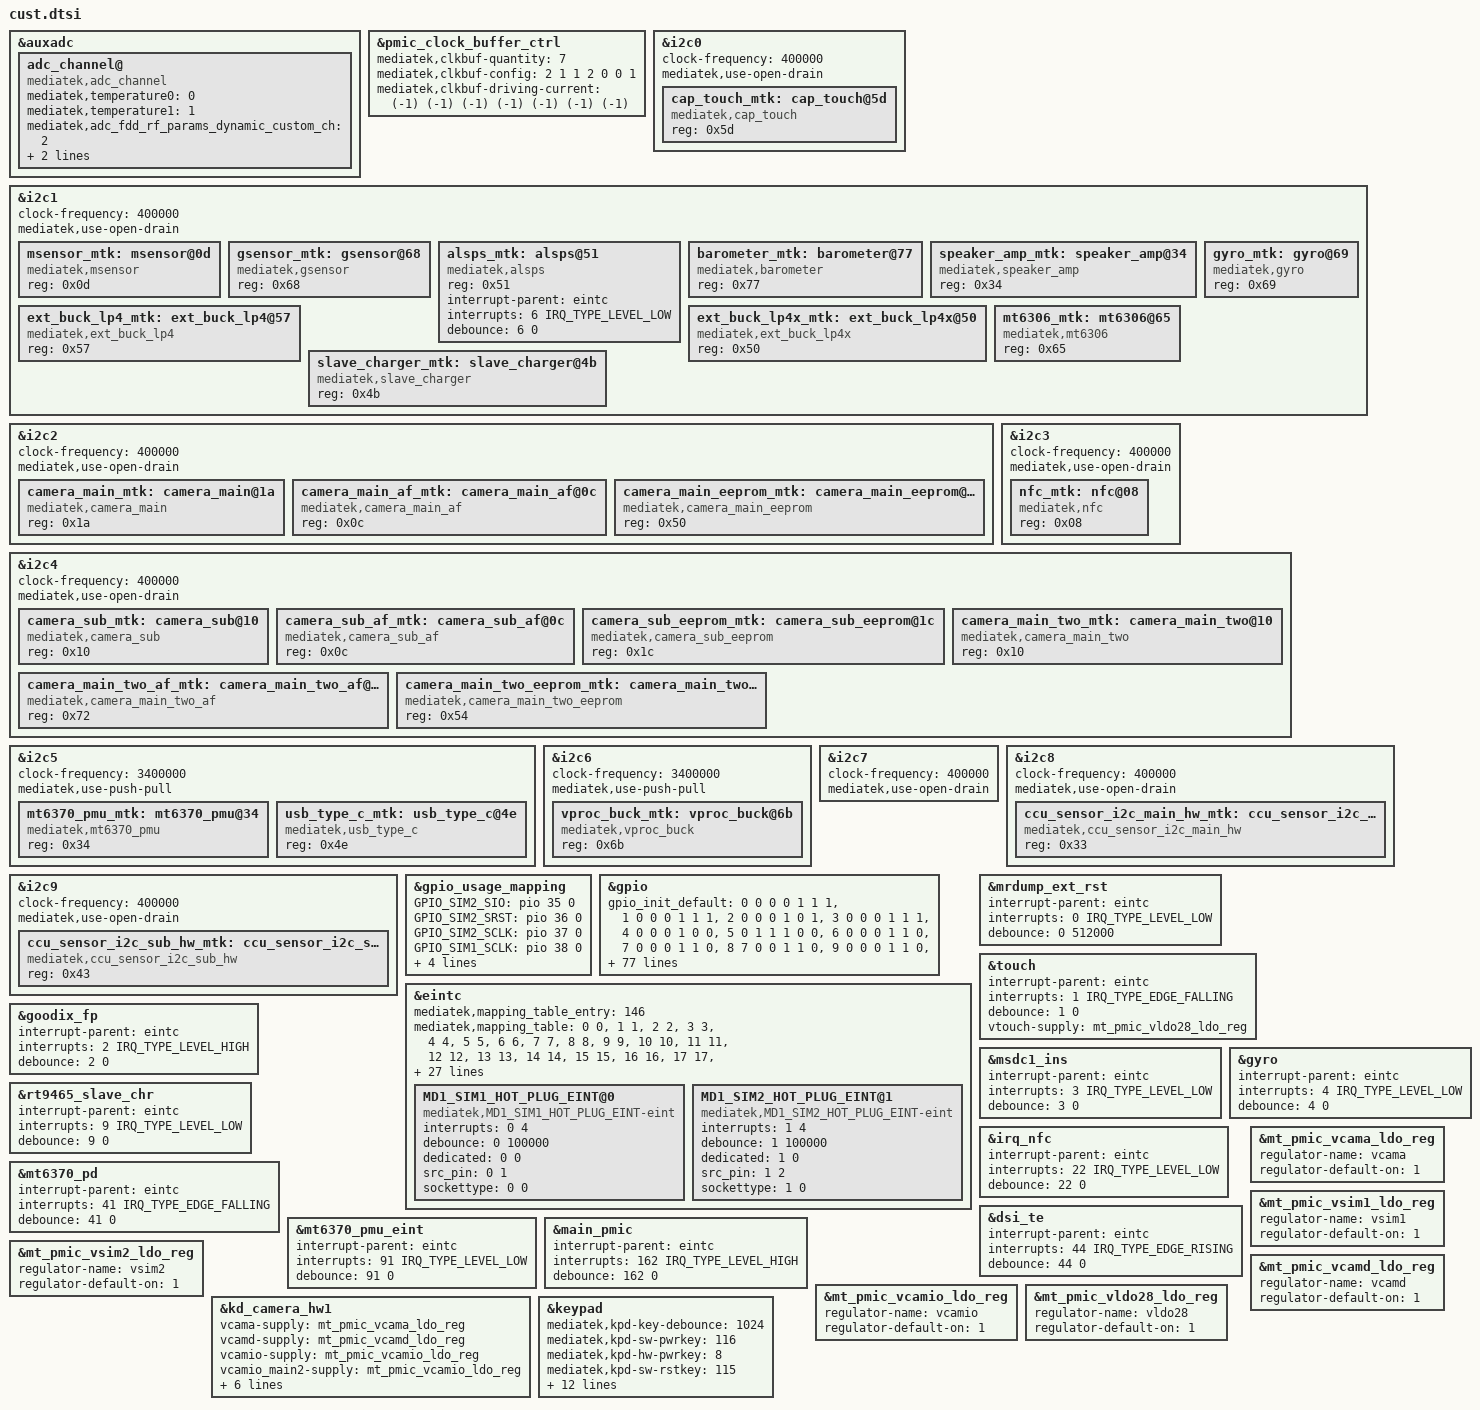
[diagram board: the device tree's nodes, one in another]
/*
 * Generated by MTK SP DrvGen Version: 3.5.160809 for MT6763.
 * 2025-11-29 21:09:34
 * Do Not Modify The File.
 * Copyright Mediatek Inc. (c) 2016.
*/

/*************************
 * ADC DTSI File
*************************/

&auxadc {
	adc_channel@ {
		compatible = "mediatek,adc_channel";
		mediatek,temperature0 = <0>;
		mediatek,temperature1 = <1>;
		mediatek,adc_fdd_rf_params_dynamic_custom_ch = <2>;
		mediatek,board_id = <3>;
		mediatek,board_id_2 = <4>;
		status = "okay";
	};
};


/*************************
 * CLK_BUF DTSI File
*************************/

&pmic_clock_buffer_ctrl {
	mediatek,clkbuf-quantity = <7>;
	mediatek,clkbuf-config = <2 1 1 2 0 0 1>;
	mediatek,clkbuf-driving-current = <(-1) (-1) (-1) (-1) (-1) (-1) (-1)>;
	status = "okay";
};


/*************************
 * I2C DTSI File
*************************/

&i2c0 {
	#address-cells = <1>;
	#size-cells = <0>;
	clock-frequency = <400000>;
	mediatek,use-open-drain;
	cap_touch_mtk:cap_touch@5d {
		compatible = "mediatek,cap_touch";
		reg = <0x5d>;
		status = "okay";
	};

};

&i2c1 {
	#address-cells = <1>;
	#size-cells = <0>;
	clock-frequency = <400000>;
	mediatek,use-open-drain;
	msensor_mtk:msensor@0d {
		compatible = "mediatek,msensor";
		reg = <0x0d>;
		status = "okay";
	};

	gsensor_mtk:gsensor@68 {
		compatible = "mediatek,gsensor";
		reg = <0x68>;
		status = "okay";
	};

	alsps_mtk:alsps@51 {
		compatible = "mediatek,alsps";
		reg = <0x51>;
		status = "okay";
	};

	barometer_mtk:barometer@77 {
		compatible = "mediatek,barometer";
		reg = <0x77>;
		status = "okay";
	};

	speaker_amp_mtk:speaker_amp@34 {
		compatible = "mediatek,speaker_amp";
		reg = <0x34>;
		status = "okay";
	};

	ext_buck_lp4_mtk:ext_buck_lp4@57 {
		compatible = "mediatek,ext_buck_lp4";
		reg = <0x57>;
		status = "okay";
	};

	ext_buck_lp4x_mtk:ext_buck_lp4x@50 {
		compatible = "mediatek,ext_buck_lp4x";
		reg = <0x50>;
		status = "okay";
	};

	gyro_mtk:gyro@69 {
		compatible = "mediatek,gyro";
		reg = <0x69>;
		status = "okay";
	};

	mt6306_mtk:mt6306@65 {
		compatible = "mediatek,mt6306";
		reg = <0x65>;
		status = "okay";
	};

	slave_charger_mtk:slave_charger@4b {
		compatible = "mediatek,slave_charger";
		reg = <0x4b>;
		status = "okay";
	};

};

&i2c2 {
	#address-cells = <1>;
	#size-cells = <0>;
	clock-frequency = <400000>;
	mediatek,use-open-drain;
	camera_main_mtk:camera_main@1a {
		compatible = "mediatek,camera_main";
		reg = <0x1a>;
		status = "okay";
	};

	camera_main_af_mtk:camera_main_af@0c {
		compatible = "mediatek,camera_main_af";
		reg = <0x0c>;
		status = "okay";
	};

	camera_main_eeprom_mtk:camera_main_eeprom@50 {
		compatible = "mediatek,camera_main_eeprom";
		reg = <0x50>;
		status = "okay";
	};

};

&i2c3 {
	#address-cells = <1>;
	#size-cells = <0>;
	clock-frequency = <400000>;
	mediatek,use-open-drain;
	nfc_mtk:nfc@08 {
		compatible = "mediatek,nfc";
		reg = <0x08>;
		status = "okay";
	};

};

&i2c4 {
	#address-cells = <1>;
	#size-cells = <0>;
	clock-frequency = <400000>;
	mediatek,use-open-drain;
	camera_sub_mtk:camera_sub@10 {
		compatible = "mediatek,camera_sub";
		reg = <0x10>;
		status = "okay";
	};

	camera_sub_af_mtk:camera_sub_af@0c {
		compatible = "mediatek,camera_sub_af";
		reg = <0x0c>;
		status = "okay";
	};

	camera_sub_eeprom_mtk:camera_sub_eeprom@1c {
		compatible = "mediatek,camera_sub_eeprom";
		reg = <0x1c>;
		status = "okay";
	};

	camera_main_two_mtk:camera_main_two@10 {
		compatible = "mediatek,camera_main_two";
		reg = <0x10>;
		status = "okay";
	};

	camera_main_two_af_mtk:camera_main_two_af@72 {
		compatible = "mediatek,camera_main_two_af";
		reg = <0x72>;
		status = "okay";
	};

	camera_main_two_eeprom_mtk:camera_main_two_eeprom@54 {
		compatible = "mediatek,camera_main_two_eeprom";
		reg = <0x54>;
		status = "okay";
	};

};

&i2c5 {
	#address-cells = <1>;
	#size-cells = <0>;
	clock-frequency = <3400000>;
	mediatek,use-push-pull;
	mt6370_pmu_mtk:mt6370_pmu@34 {
		compatible = "mediatek,mt6370_pmu";
		reg = <0x34>;
		status = "okay";
	};

	usb_type_c_mtk:usb_type_c@4e {
		compatible = "mediatek,usb_type_c";
		reg = <0x4e>;
		status = "okay";
	};

};

&i2c6 {
	#address-cells = <1>;
	#size-cells = <0>;
	clock-frequency = <3400000>;
	mediatek,use-push-pull;
	vproc_buck_mtk:vproc_buck@6b {
		compatible = "mediatek,vproc_buck";
		reg = <0x6b>;
		status = "okay";
	};

};

&i2c7 {
	#address-cells = <1>;
	#size-cells = <0>;
	clock-frequency = <400000>;
	mediatek,use-open-drain;
};

&i2c8 {
	#address-cells = <1>;
	#size-cells = <0>;
	clock-frequency = <400000>;
	mediatek,use-open-drain;
	ccu_sensor_i2c_main_hw_mtk:ccu_sensor_i2c_main_hw@33 {
		compatible = "mediatek,ccu_sensor_i2c_main_hw";
		reg = <0x33>;
		status = "okay";
	};

};

&i2c9 {
	#address-cells = <1>;
	#size-cells = <0>;
	clock-frequency = <400000>;
	mediatek,use-open-drain;
	ccu_sensor_i2c_sub_hw_mtk:ccu_sensor_i2c_sub_hw@43 {
		compatible = "mediatek,ccu_sensor_i2c_sub_hw";
		reg = <0x43>;
		status = "okay";
	};

};



/*************************
 * GPIO DTSI File
*************************/

&gpio_usage_mapping {
	GPIO_SIM2_SIO = <&pio 35 0>;
	GPIO_SIM2_SRST = <&pio 36 0>;
	GPIO_SIM2_SCLK = <&pio 37 0>;
	GPIO_SIM1_SCLK = <&pio 38 0>;
	GPIO_SIM1_SRST = <&pio 39 0>;
	GPIO_SIM1_SIO = <&pio 40 0>;
	GPIO_SIM2_HOT_PLUG = <&pio 46 0>;
	GPIO_SIM1_HOT_PLUG = <&pio 47 0>;
};

&gpio{
	gpio_init_default = <0 0 0 0 1 1 1>,
		<1 0 0 0 1 1 1>,
		<2 0 0 0 1 0 1>,
		<3 0 0 0 1 1 1>,
		<4 0 0 0 1 0 0>,
		<5 0 1 1 1 0 0>,
		<6 0 0 0 1 1 0>,
		<7 0 0 0 1 1 0>,
		<8 7 0 0 1 1 0>,
		<9 0 0 0 1 1 0>,
		<10 0 1 0 0 0 0>,
		<11 3 0 0 1 1 0>,
		<12 3 0 0 1 1 0>,
		<13 2 1 0 1 0 0>,
		<14 2 1 0 1 0 0>,
		<15 2 1 0 1 0 0>,
		<16 2 0 0 1 0 0>,
		<17 0 1 0 0 0 0>,
		<18 0 1 0 0 0 0>,
		<19 0 0 0 0 0 0>,
		<20 0 0 0 1 1 0>,
		<21 0 1 1 1 1 0>,
		<22 0 0 0 1 0 0>,
		<23 0 0 0 0 0 0>,
		<24 5 0 0 1 0 0>,
		<25 5 0 0 1 0 0>,
		<26 5 0 0 1 0 0>,
		<27 5 1 0 1 0 0>,
		<28 5 0 0 1 0 0>,
		<29 1 1 0 1 0 0>,
		<30 1 0 0 1 1 0>,
		<31 1 0 0 1 1 0>,
		<32 1 0 0 1 1 0>,
		<33 1 0 0 1 1 0>,
		<34 1 0 0 1 1 0>,
		<35 1 0 0 1 1 0>,
		<36 1 1 0 1 0 0>,
		<37 1 1 0 1 0 0>,
		<38 1 1 0 1 0 0>,
		<39 1 1 0 1 0 0>,
		<40 1 0 0 1 1 0>,
		<41 0 0 0 1 1 0>,
		<42 1 1 0 1 0 0>,
		<43 1 1 0 1 0 0>,
		<44 1 0 0 1 0 0>,
		<45 1 1 0 0 0 0>,
		<46 1 0 0 1 1 0>,
		<47 1 0 0 1 1 0>,
		<48 1 0 0 1 1 0>,
		<49 1 0 0 1 1 0>,
		<50 1 0 0 1 1 0>,
		<51 1 0 0 1 1 0>,
		<52 1 1 0 1 0 0>,
		<53 1 1 0 1 0 0>,
		<54 1 1 0 1 0 0>,
		<55 1 1 0 1 0 0>,
		<56 1 1 0 1 0 0>,
		<57 1 1 0 1 0 0>,
		<58 1 1 0 0 0 0>,
		<59 1 1 0 1 0 0>,
		<60 1 1 0 1 0 0>,
		<61 1 0 0 1 0 0>,
		<62 1 0 0 1 0 0>,
		<63 1 0 0 1 0 0>,
		<64 1 0 0 1 0 0>,
		<65 2 0 0 1 0 0>,
		<66 2 0 0 1 0 0>,
		<67 1 0 0 1 0 0>,
		<68 1 0 0 1 0 0>,
		<69 1 1 0 1 0 0>,
		<70 1 1 0 1 0 0>,
		<71 1 0 0 1 0 0>,
		<72 1 0 0 1 0 0>,
		<73 1 1 0 1 0 0>,
		<74 1 1 0 1 0 0>,
		<75 1 1 0 1 0 0>,
		<76 1 1 0 1 0 0>,
		<77 1 1 0 1 0 0>,
		<78 1 1 0 1 0 0>,
		<79 1 1 0 1 0 0>,
		<80 1 1 0 1 0 0>,
		<81 1 0 0 1 1 0>,
		<82 1 0 0 1 1 0>,
		<83 1 0 0 1 1 0>,
		<84 1 0 0 1 1 0>,
		<85 7 1 0 1 0 0>,
		<86 7 0 0 1 0 0>,
		<87 7 0 0 1 0 0>,
		<88 7 1 0 1 0 0>,
		<89 1 0 0 1 0 0>,
		<90 0 1 0 0 0 0>,
		<91 0 0 0 1 1 0>,
		<92 1 1 0 0 0 0>,
		<93 1 0 0 1 1 0>,
		<94 1 0 0 1 1 0>,
		<95 1 0 0 1 1 0>,
		<96 1 1 1 0 0 0>,
		<97 0 1 0 0 0 0>,
		<98 0 1 0 0 0 0>,
		<99 0 1 0 0 0 0>,
		<100 0 1 0 0 0 0>,
		<101 0 1 0 0 0 0>,
		<102 0 1 0 0 0 0>,
		<103 1 0 0 1 1 0>,
		<104 1 0 0 1 1 0>,
		<105 1 0 0 1 1 0>,
		<106 1 0 0 1 1 0>,
		<107 0 1 0 0 0 0>,
		<108 0 1 1 0 0 0>,
		<109 0 1 0 0 0 0>,
		<110 2 1 0 1 0 0>,
		<111 2 0 0 1 1 0>,
		<112 0 0 0 1 0 0>,
		<113 0 0 0 1 0 0>,
		<114 2 0 0 1 0 0>,
		<115 0 0 0 1 0 0>,
		<116 2 0 0 1 0 0>,
		<117 2 0 0 1 0 0>,
		<118 2 1 0 1 0 0>,
		<119 2 0 0 1 0 0>,
		<120 2 0 0 1 0 0>,
		<121 2 0 0 1 0 0>,
		<122 1 0 0 1 0 0>,
		<123 1 0 0 1 0 0>,
		<124 1 1 0 1 0 0>,
		<125 1 0 0 1 0 0>,
		<126 1 0 0 1 0 0>,
		<127 1 0 0 1 0 0>,
		<128 1 0 0 1 0 0>,
		<129 1 0 0 1 0 0>,
		<130 1 0 0 1 0 0>,
		<131 1 0 0 0 0 0>,
		<132 1 0 0 1 0 0>,
		<133 1 1 0 1 0 0>,
		<134 1 0 0 0 0 1>,
		<135 1 1 0 0 0 0>,
		<136 1 0 0 0 0 0>,
		<137 1 0 0 0 0 0>,
		<138 1 0 0 0 0 0>,
		<139 1 0 0 0 0 0>,
		<140 1 0 0 0 0 0>,
		<141 1 0 0 0 0 0>,
		<142 1 0 0 0 0 0>,
		<143 1 0 0 0 0 0>,
		<144 1 0 0 0 0 0>,
		<145 1 1 1 0 0 0>,
		<146 1 0 0 0 0 0>,
		<147 1 0 0 0 0 0>,
		<148 1 1 1 0 0 0>,
		<149 1 1 0 0 0 0>,
		<150 1 1 0 1 0 0>,
		<151 1 1 0 1 0 0>,
		<152 0 0 0 1 0 0>,
		<153 0 0 0 1 0 0>,
		<154 0 0 0 1 0 0>,
		<155 0 0 0 1 0 0>,
		<156 0 0 0 1 0 0>,
		<157 0 0 0 1 0 0>,
		<158 0 0 0 1 0 0>,
		<159 0 0 0 1 0 0>,
		<160 0 0 0 1 0 0>,
		<161 0 0 0 1 0 0>,
		<162 0 0 0 1 0 0>,
		<163 0 0 0 1 0 0>;
};


/*************************
 * EINT DTSI File
*************************/

#include <dt-bindings/interrupt-controller/irq.h>
#include <dt-bindings/interrupt-controller/arm-gic.h>

&eintc {
	mediatek,mapping_table_entry = <146>;
			/* <gpio_pin, eint_pin> */
	mediatek,mapping_table = <0 0>,
					<1 1>,
					<2 2>,
					<3 3>,
					<4 4>,
					<5 5>,
					<6 6>,
					<7 7>,
					<8 8>,
					<9 9>,
					<10 10>,
					<11 11>,
					<12 12>,
					<13 13>,
					<14 14>,
					<15 15>,
					<16 16>,
					<17 17>,
					<18 18>,
					<19 19>,
					<20 20>,
					<21 21>,
					<22 22>,
					<23 23>,
					<24 24>,
					<25 25>,
					<26 26>,
					<27 27>,
					<28 28>,
					<29 29>,
					<30 30>,
					<31 31>,
					<32 32>,
					<33 33>,
					<34 34>,
					<35 35>,
					<36 36>,
					<37 37>,
					<38 38>,
					<39 39>,
					<40 40>,
					<41 41>,
					<42 42>,
					<43 43>,
					<44 44>,
					<45 45>,
					<46 46>,
					<47 47>,
					<48 48>,
					<49 49>,
					<50 50>,
					<51 51>,
					<52 52>,
					<53 53>,
					<54 54>,
					<55 55>,
					<56 56>,
					<57 57>,
					<58 58>,
					<59 59>,
					<60 60>,
					<61 61>,
					<62 62>,
					<63 63>,
					<64 64>,
					<65 65>,
					<66 66>,
					<67 67>,
					<68 68>,
					<69 69>,
					<70 70>,
					<71 71>,
					<72 72>,
					<73 73>,
					<74 74>,
					<75 75>,
					<76 76>,
					<77 77>,
					<78 78>,
					<79 79>,
					<80 80>,
					<81 81>,
					<82 82>,
					<83 83>,
					<84 84>,
					<85 85>,
					<86 86>,
					<87 87>,
					<88 88>,
					<89 89>,
					<90 90>,
					<91 91>,
					<92 92>,
					<93 93>,
					<94 94>,
					<95 95>,
					<96 96>,
					<97 97>,
					<98 98>,
					<99 99>,
					<100 100>,
					<101 101>,
					<102 102>,
					<103 103>,
					<104 104>,
					<105 105>,
					<106 106>,
					<107 107>,
					<108 108>,
					<109 109>,
					<110 110>,
					<111 111>,
					<112 112>,
					<113 113>,
					<114 114>,
					<115 115>,
					<116 116>,
					<117 117>,
					<118 118>,
					<119 119>,
					<120 120>,
					<121 121>,
					<122 122>,
					<123 123>,
					<124 124>,
					<125 125>,
					<126 126>,
					<127 127>,
					<128 128>,
					<129 129>,
					<130 130>,
					<131 131>,
					<132 132>,
					<133 133>,
					<152 139>,
					<153 140>,
					<154 141>,
					<155 142>,
					<156 143>,
					<157 145>,
					<158 146>,
					<159 147>,
					<160 148>,
					<161 149>,
					<162 150>,
					<163 151>;
	mediatek,builtin_entry = <7>;
					/* gpio, built-in func mode, built-in eint */
	mediatek,builtin_mapping = <11 2 144>, /* 2:IDDIG */
					<23 2 144>, /* 2:IDDIG */
					<46 6 144>, /* 6:IDDIG */
					<41 1 144>, /* 1:IDDIG */
					<0 4 144>, /* 4:IDDIG */
					<109 4 144>, /* 4:IDDIG */
					<6 3 144>;};

&mrdump_ext_rst {
	interrupt-parent = <&eintc>;
	interrupts = <0 IRQ_TYPE_LEVEL_LOW>;
	debounce = <0 512000>;
	status = "okay";
};

&touch {
	interrupt-parent = <&eintc>;
	interrupts = <1 IRQ_TYPE_EDGE_FALLING>;
	debounce = <1 0>;
	status = "okay";
};

&goodix_fp {
	interrupt-parent = <&eintc>;
	interrupts = <2 IRQ_TYPE_LEVEL_HIGH>;
	debounce = <2 0>;
	status = "okay";
};

&msdc1_ins {
	interrupt-parent = <&eintc>;
	interrupts = <3 IRQ_TYPE_LEVEL_LOW>;
	debounce = <3 0>;
	status = "okay";
};

&gyro {
	interrupt-parent = <&eintc>;
	interrupts = <4 IRQ_TYPE_LEVEL_LOW>;
	debounce = <4 0>;
	status = "okay";
};

&alsps_mtk {
	interrupt-parent = <&eintc>;
	interrupts = <6 IRQ_TYPE_LEVEL_LOW>;
	debounce = <6 0>;
	status = "okay";
};

&rt9465_slave_chr {
	interrupt-parent = <&eintc>;
	interrupts = <9 IRQ_TYPE_LEVEL_LOW>;
	debounce = <9 0>;
	status = "okay";
};

&irq_nfc {
	interrupt-parent = <&eintc>;
	interrupts = <22 IRQ_TYPE_LEVEL_LOW>;
	debounce = <22 0>;
	status = "okay";
};

&mt6370_pd {
	interrupt-parent = <&eintc>;
	interrupts = <41 IRQ_TYPE_EDGE_FALLING>;
	debounce = <41 0>;
	status = "okay";
};

&dsi_te {
	interrupt-parent = <&eintc>;
	interrupts = <44 IRQ_TYPE_EDGE_RISING>;
	debounce = <44 0>;
	status = "okay";
};

&mt6370_pmu_eint {
	interrupt-parent = <&eintc>;
	interrupts = <91 IRQ_TYPE_LEVEL_LOW>;
	debounce = <91 0>;
	status = "okay";
};

&main_pmic {
	interrupt-parent = <&eintc>;
	interrupts = <162 IRQ_TYPE_LEVEL_HIGH>;
	debounce = <162 0>;
	status = "okay";
};



/*************************
 * MD1_EINT DTSI File
*************************/

&eintc {
	MD1_SIM1_HOT_PLUG_EINT@0 {
		compatible = "mediatek,MD1_SIM1_HOT_PLUG_EINT-eint";
		interrupts = <0 4>;
		debounce = <0 100000>;
		dedicated = <0 0>;
		src_pin = <0 1>;
		sockettype = <0 0>;
		status = "okay";
	};

	MD1_SIM2_HOT_PLUG_EINT@1 {
		compatible = "mediatek,MD1_SIM2_HOT_PLUG_EINT-eint";
		interrupts = <1 4>;
		debounce = <1 100000>;
		dedicated = <1 0>;
		src_pin = <1 2>;
		sockettype = <1 0>;
		status = "okay";
	};

};


/*************************
 * PMIC DTSI File
*************************/

&mt_pmic_vcama_ldo_reg {
	regulator-name = "vcama";
	regulator-default-on = <1>; /* 0:skip, 1: off, 2:on */
	status = "okay";
};
&mt_pmic_vsim1_ldo_reg {
	regulator-name = "vsim1";
	regulator-default-on = <1>; /* 0:skip, 1: off, 2:on */
	status = "okay";
};
&mt_pmic_vsim2_ldo_reg {
	regulator-name = "vsim2";
	regulator-default-on = <1>; /* 0:skip, 1: off, 2:on */
	status = "okay";
};
&mt_pmic_vcamd_ldo_reg {
	regulator-name = "vcamd";
	regulator-default-on = <1>; /* 0:skip, 1: off, 2:on */
	status = "okay";
};
&mt_pmic_vcamio_ldo_reg {
	regulator-name = "vcamio";
	regulator-default-on = <1>; /* 0:skip, 1: off, 2:on */
	status = "okay";
};
&mt_pmic_vldo28_ldo_reg {
	regulator-name = "vldo28";
	regulator-default-on = <1>; /* 0:skip, 1: off, 2:on */
	status = "okay";
};

&kd_camera_hw1 {
	vcama-supply = <&mt_pmic_vcama_ldo_reg>;
	vcamd-supply = <&mt_pmic_vcamd_ldo_reg>;
	vcamio-supply = <&mt_pmic_vcamio_ldo_reg>;
	vcamio_main2-supply = <&mt_pmic_vcamio_ldo_reg>;
	vcamio_sub-supply = <&mt_pmic_vcamio_ldo_reg>;
	vcama_main2-supply = <&mt_pmic_vcamio_ldo_reg>;
	vcama_sub-supply = <&mt_pmic_vcamio_ldo_reg>;
	vcamaf-supply = <&mt_pmic_vldo28_ldo_reg>;
	vcamaf_main2-supply = <&mt_pmic_vldo28_ldo_reg>;
	vcamaf_sub-supply = <&mt_pmic_vldo28_ldo_reg>;
	status = "okay";
};

&touch {
	vtouch-supply = <&mt_pmic_vldo28_ldo_reg>;
	status = "okay";
};


/*************************
 * POWER DTSI File
*************************/



/*************************
 * KPD DTSI File
*************************/

&keypad {
	mediatek,kpd-key-debounce = <1024>;
	mediatek,kpd-sw-pwrkey = <116>;
	mediatek,kpd-hw-pwrkey = <8>;
	mediatek,kpd-sw-rstkey  = <115>;
	mediatek,kpd-hw-rstkey = <17>;
	mediatek,kpd-use-extend-type = <0>;
	/*HW Keycode [0~71] -> Linux Keycode*/
	mediatek,kpd-hw-map-num = <72>;
	mediatek,kpd-hw-init-map = <114 0 0 0 0 0 0 0 0 0 0 0 0 0 0 0 0 0 0 0 0 0 0 0 0 0 0 0 0 0 0 0 0 0 0 0 0 0 0 0 0 0 0 0 0 0 0 0 0 0 0 0 0 0 0 0 0 0 0 0 0 0 0 0 0 0 0 0 0 0 0 0 >;
	mediatek,kpd-pwrkey-eint-gpio = <0>;
	mediatek,kpd-pwkey-gpio-din  = <0>;
	mediatek,kpd-hw-dl-key0 = <17>;
	mediatek,kpd-hw-dl-key1 = <0>;
	mediatek,kpd-hw-dl-key2 = <8>;
	mediatek,kpd-hw-recovery-key = <17>;
	mediatek,kpd-hw-factory-key = <0>;
	status = "okay";
};


